# PIC32MX130F128L register map
Vendor: Microchip
Registers are 32-bit, read-write, reset 0x0 unless marked. A register's access mark holds for its fields unless they carry their own. Addresses are absolute, and some are shared; only a register's first bit layout is shown; [hi:lo] are bit positions; {n}, {i} and the like mark numbered series.

## PORTA
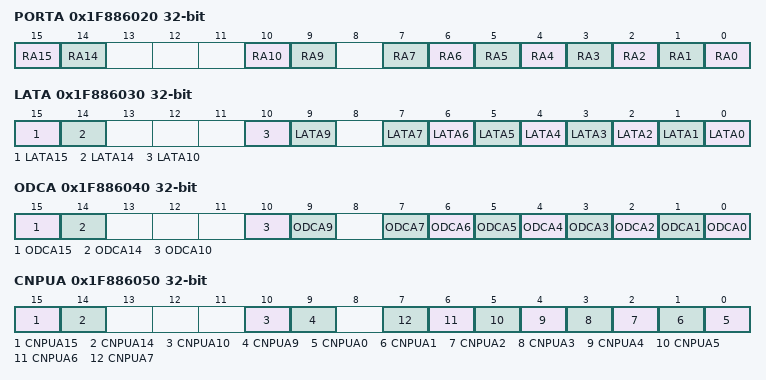
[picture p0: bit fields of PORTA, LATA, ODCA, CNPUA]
0x1F886020 PORTA reset not defined — (power-on value ----------------xx---xx-xxxxxxxx)
  [15] RA15, [14] RA14, [10] RA10, [9] RA9, [n] RA{n} (n=0..7)
0x1F886030 LATA reset not defined — (power-on value ----------------xx---xx-xxxxxxxx)
  [15] LATA15, [14] LATA14, [10] LATA10, [9] LATA9, [n] LATA{n} (n=0..7)
0x1F886040 ODCA
  [15] ODCA15, [14] ODCA14, [10] ODCA10, [9] ODCA9, [n] ODCA{n} (n=0..7)
0x1F886050 CNPUA reset not defined — (power-on value ----------------xx---xx-xxxxxxxx)
  [15] CNPUA15, [14] CNPUA14, [10] CNPUA10, [9] CNPUA9, [n] CNPUA{n} (n=0..7)
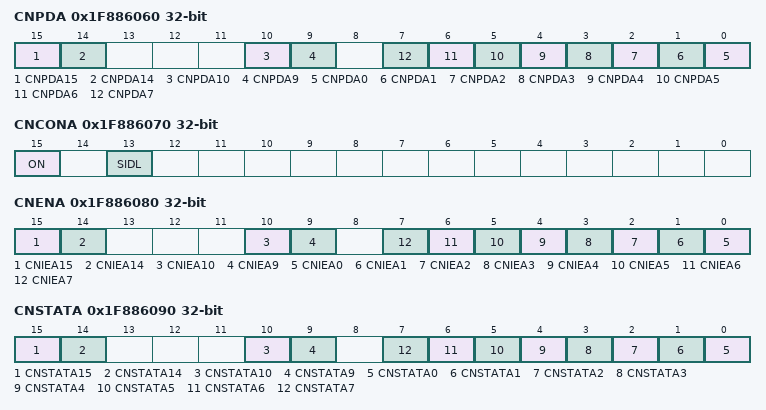
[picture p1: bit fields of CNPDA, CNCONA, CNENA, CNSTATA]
0x1F886060 CNPDA reset not defined — (power-on value ----------------xx---xx-xxxxxxxx)
  [15] CNPDA15, [14] CNPDA14, [10] CNPDA10, [9] CNPDA9, [n] CNPDA{n} (n=0..7)
0x1F886070 CNCONA
  [15] ON, [13] SIDL
0x1F886080 CNENA reset not defined — (power-on value 0000000000------xx---xx-xxxxxxxx)
  [15] CNIEA15, [14] CNIEA14, [10] CNIEA10, [9] CNIEA9, [n] CNIEA{n} (n=0..7)
0x1F886090 CNSTATA reset not defined — (power-on value ----------------xx---xx-xxxxxxxx)
  [15] CNSTATA15, [14] CNSTATA14, [10] CNSTATA10, [9] CNSTATA9, [n] CNSTATA{n} (n=0..7)

## PORTB
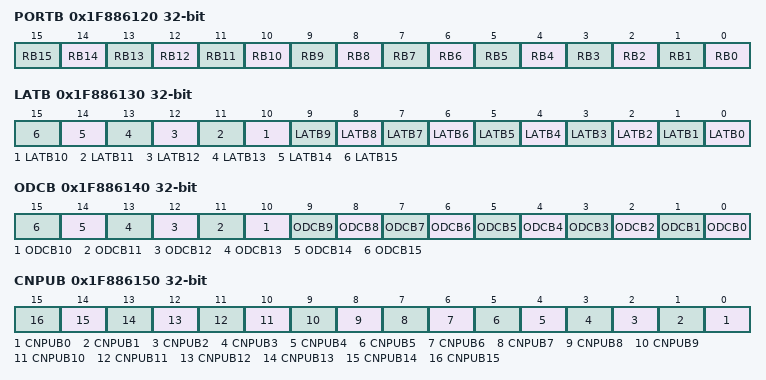
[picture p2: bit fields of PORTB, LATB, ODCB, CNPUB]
0x1F886120 PORTB reset not defined — (power-on value ----------------xxxxxxxxxxxxxxxx)
  [n] RB{n} (n=0..15)
0x1F886130 LATB reset not defined — (power-on value ----------------xxxxxxxxxxxxxxxx)
  [n] LATB{n} (n=0..15)
0x1F886140 ODCB
  [n] ODCB{n} (n=0..15)
0x1F886150 CNPUB reset not defined — (power-on value ----------------xxxxxxxxxxxxxxxx)
  [n] CNPUB{n} (n=0..15)
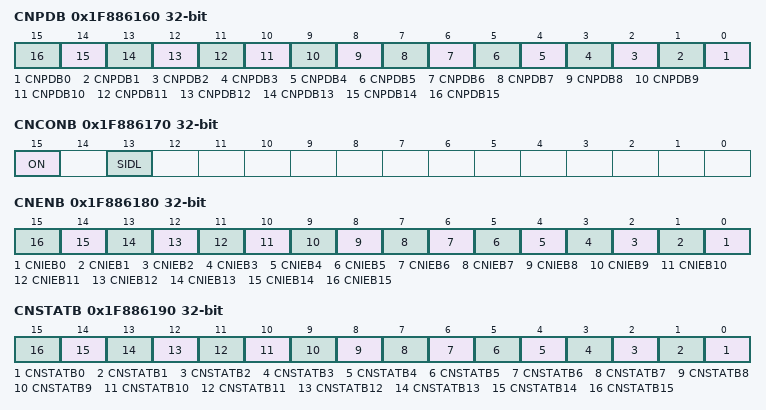
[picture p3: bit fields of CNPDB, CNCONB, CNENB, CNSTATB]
0x1F886160 CNPDB reset not defined — (power-on value ----------------xxxxxxxxxxxxxxxx)
  [n] CNPDB{n} (n=0..15)
0x1F886170 CNCONB
  [15] ON, [13] SIDL
0x1F886180 CNENB reset not defined — (power-on value 0000000000------xxxxxxxxxxxxxxxx)
  [n] CNIEB{n} (n=0..15)
0x1F886190 CNSTATB reset not defined — (power-on value ----------------xxxxxxxxxxxxxxxx)
  [n] CNSTATB{n} (n=0..15)

## PORTC
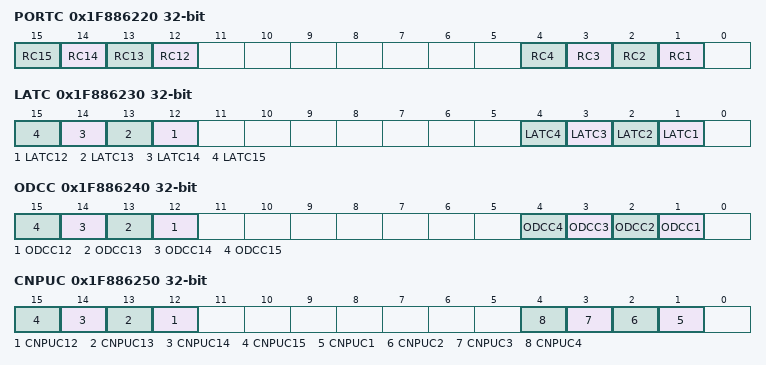
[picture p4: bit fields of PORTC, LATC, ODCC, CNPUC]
0x1F886220 PORTC reset not defined — (power-on value ----------------xxxx-------xxxx-)
  [n] RC{n} (n=12..15), [n] RC{n} (n=1..4)
0x1F886230 LATC reset not defined — (power-on value ----------------xxxx-------xxxx-)
  [n] LATC{n} (n=12..15), [n] LATC{n} (n=1..4)
0x1F886240 ODCC
  [n] ODCC{n} (n=12..15), [n] ODCC{n} (n=1..4)
0x1F886250 CNPUC reset not defined — (power-on value ----------------xxxx-------xxxx-)
  [n] CNPUC{n} (n=12..15), [n] CNPUC{n} (n=1..4)
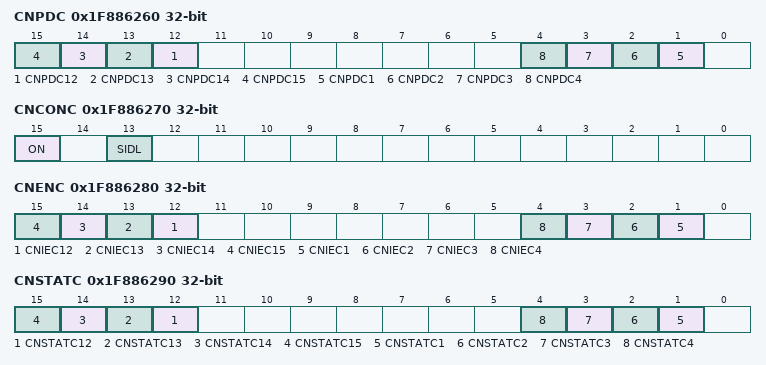
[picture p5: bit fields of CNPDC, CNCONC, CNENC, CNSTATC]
0x1F886260 CNPDC reset not defined — (power-on value ----------------xxxx-------xxxx-)
  [n] CNPDC{n} (n=12..15), [n] CNPDC{n} (n=1..4)
0x1F886270 CNCONC
  [15] ON, [13] SIDL
0x1F886280 CNENC reset not defined — (power-on value 0000000000------xxxx-------xxxx-)
  [n] CNIEC{n} (n=12..15), [n] CNIEC{n} (n=1..4)
0x1F886290 CNSTATC reset not defined — (power-on value ----------------xxxx-------xxxx-)
  [n] CNSTATC{n} (n=12..15), [n] CNSTATC{n} (n=1..4)

## PORTD
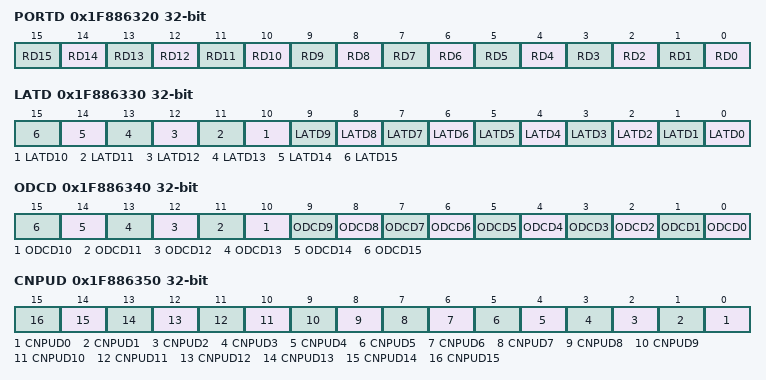
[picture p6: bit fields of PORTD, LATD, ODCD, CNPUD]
0x1F886320 PORTD reset not defined — (power-on value ----------------xxxxxxxxxxxxxxxx)
  [n] RD{n} (n=0..15)
0x1F886330 LATD reset not defined — (power-on value ----------------xxxxxxxxxxxxxxxx)
  [n] LATD{n} (n=0..15)
0x1F886340 ODCD
  [n] ODCD{n} (n=0..15)
0x1F886350 CNPUD reset not defined — (power-on value ----------------xxxxxxxxxxxxxxxx)
  [n] CNPUD{n} (n=0..15)
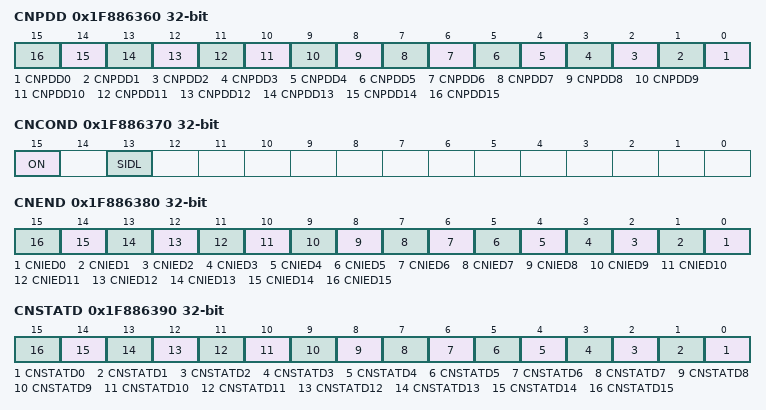
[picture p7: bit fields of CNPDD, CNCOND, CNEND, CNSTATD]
0x1F886360 CNPDD reset not defined — (power-on value ----------------xxxxxxxxxxxxxxxx)
  [n] CNPDD{n} (n=0..15)
0x1F886370 CNCOND
  [15] ON, [13] SIDL
0x1F886380 CNEND reset not defined — (power-on value 0000000000------xxxxxxxxxxxxxxxx)
  [n] CNIED{n} (n=0..15)
0x1F886390 CNSTATD reset not defined — (power-on value ----------------xxxxxxxxxxxxxxxx)
  [n] CNSTATD{n} (n=0..15)

## PORTE
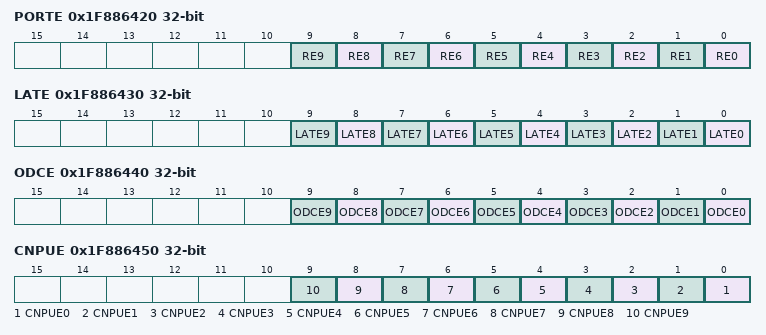
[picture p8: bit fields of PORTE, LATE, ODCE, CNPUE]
0x1F886420 PORTE reset not defined — (power-on value ----------------------xxxxxxxxxx)
  [n] RE{n} (n=0..9)
0x1F886430 LATE reset not defined — (power-on value ----------------------xxxxxxxxxx)
  [n] LATE{n} (n=0..9)
0x1F886440 ODCE
  [n] ODCE{n} (n=0..9)
0x1F886450 CNPUE reset not defined — (power-on value ----------------------xxxxxxxxxx)
  [n] CNPUE{n} (n=0..9)
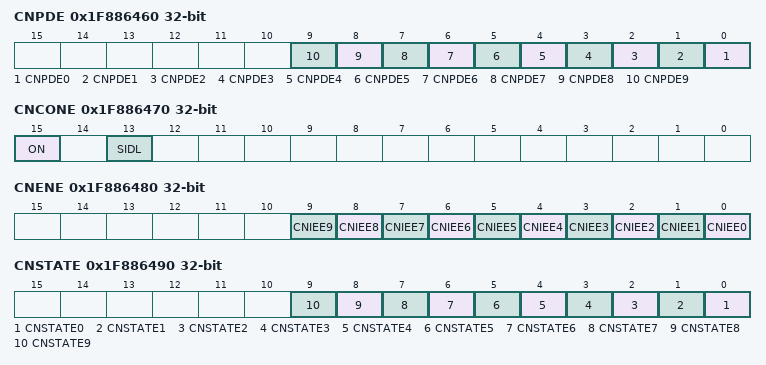
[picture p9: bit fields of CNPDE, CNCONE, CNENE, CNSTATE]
0x1F886460 CNPDE reset not defined — (power-on value ----------------------xxxxxxxxxx)
  [n] CNPDE{n} (n=0..9)
0x1F886470 CNCONE
  [15] ON, [13] SIDL
0x1F886480 CNENE reset not defined — (power-on value 0000000000------------xxxxxxxxxx)
  [n] CNIEE{n} (n=0..9)
0x1F886490 CNSTATE reset not defined — (power-on value ----------------------xxxxxxxxxx)
  [n] CNSTATE{n} (n=0..9)

## PORTF
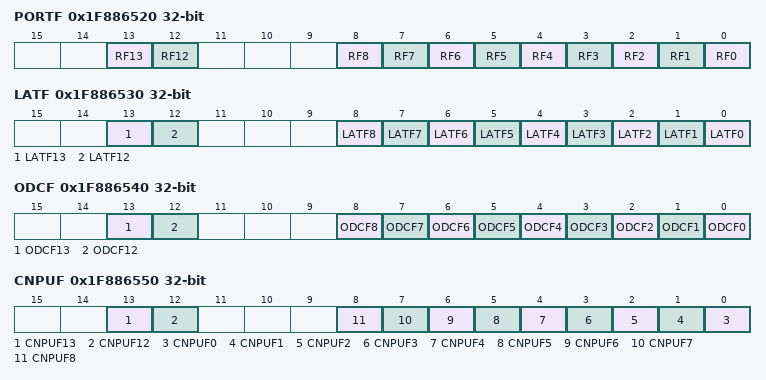
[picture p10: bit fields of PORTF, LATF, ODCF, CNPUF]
0x1F886520 PORTF reset not defined — (power-on value ------------------xx---xxxxxxxxx)
  [13] RF13, [12] RF12, [n] RF{n} (n=0..8)
0x1F886530 LATF reset not defined — (power-on value ------------------xx---xxxxxxxxx)
  [13] LATF13, [12] LATF12, [n] LATF{n} (n=0..8)
0x1F886540 ODCF
  [13] ODCF13, [12] ODCF12, [n] ODCF{n} (n=0..8)
0x1F886550 CNPUF reset not defined — (power-on value ------------------xx---xxxxxxxxx)
  [13] CNPUF13, [12] CNPUF12, [n] CNPUF{n} (n=0..8)
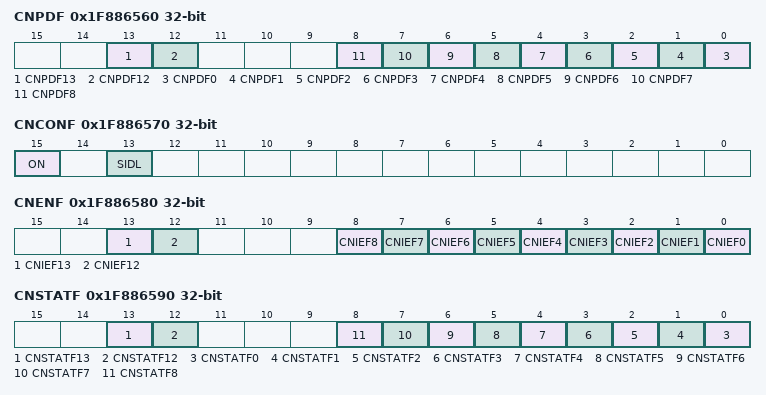
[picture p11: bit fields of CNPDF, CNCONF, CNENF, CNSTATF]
0x1F886560 CNPDF reset not defined — (power-on value ------------------xx---xxxxxxxxx)
  [13] CNPDF13, [12] CNPDF12, [n] CNPDF{n} (n=0..8)
0x1F886570 CNCONF
  [15] ON, [13] SIDL
0x1F886580 CNENF reset not defined — (power-on value 0000000000--------xx---xxxxxxxxx)
  [13] CNIEF13, [12] CNIEF12, [n] CNIEF{n} (n=0..8)
0x1F886590 CNSTATF reset not defined — (power-on value ------------------xx---xxxxxxxxx)
  [13] CNSTATF13, [12] CNSTATF12, [n] CNSTATF{n} (n=0..8)

## PORTG
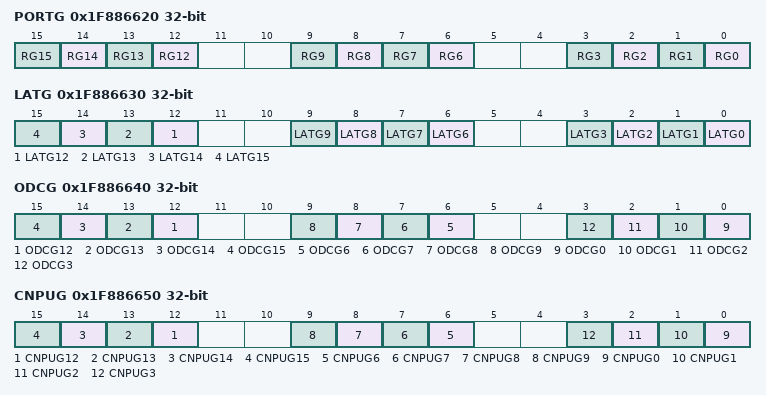
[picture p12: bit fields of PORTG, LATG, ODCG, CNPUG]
0x1F886620 PORTG reset not defined — (power-on value ----------------xxxx--xxxx--xxxx)
  [n] RG{n} (n=12..15), [n] RG{n} (n=6..9), [n] RG{n} (n=0..3)
0x1F886630 LATG reset not defined — (power-on value ----------------xxxx--xxxx--xxxx)
  [n] LATG{n} (n=12..15), [n] LATG{n} (n=6..9), [n] LATG{n} (n=0..3)
0x1F886640 ODCG
  [n] ODCG{n} (n=12..15), [n] ODCG{n} (n=6..9), [n] ODCG{n} (n=0..3)
0x1F886650 CNPUG reset not defined — (power-on value ----------------xxxx--xxxx--xxxx)
  [n] CNPUG{n} (n=12..15), [n] CNPUG{n} (n=6..9), [n] CNPUG{n} (n=0..3)
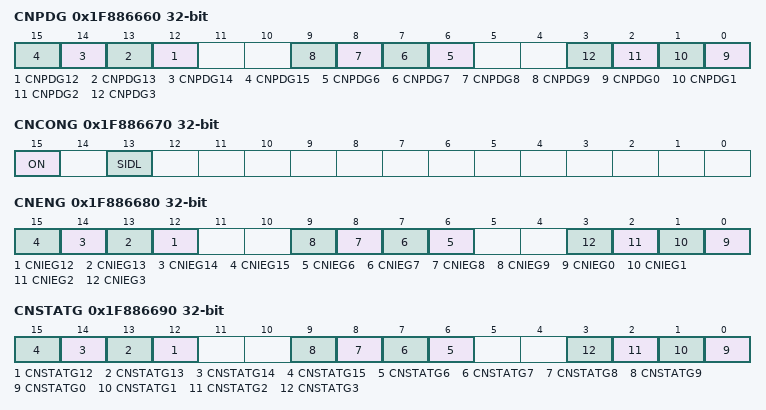
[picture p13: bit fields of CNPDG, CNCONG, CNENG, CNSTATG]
0x1F886660 CNPDG reset not defined — (power-on value ----------------xxxx--xxxx--xxxx)
  [n] CNPDG{n} (n=12..15), [n] CNPDG{n} (n=6..9), [n] CNPDG{n} (n=0..3)
0x1F886670 CNCONG
  [15] ON, [13] SIDL
0x1F886680 CNENG reset not defined — (power-on value 0000000000------xxxx--xxxx--xxxx)
  [n] CNIEG{n} (n=12..15), [n] CNIEG{n} (n=6..9), [n] CNIEG{n} (n=0..3)
0x1F886690 CNSTATG reset not defined — (power-on value ----------------xxxx--xxxx--xxxx)
  [n] CNSTATG{n} (n=12..15), [n] CNSTATG{n} (n=6..9), [n] CNSTATG{n} (n=0..3)
